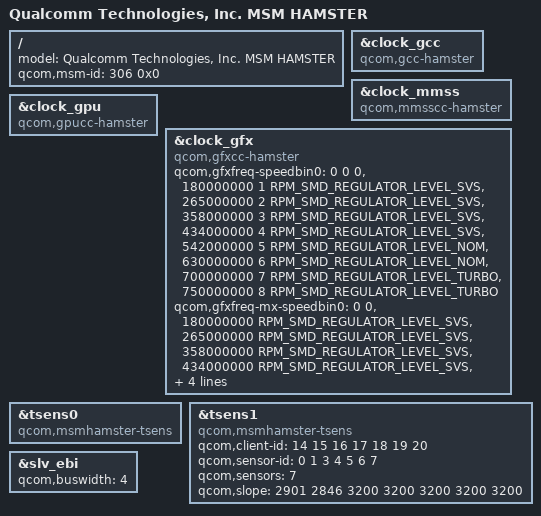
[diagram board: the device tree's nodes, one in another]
/* Copyright (c) 2016, The Linux Foundation. All rights reserved.
 *
 * This program is free software; you can redistribute it and/or modify
 * it under the terms of the GNU General Public License version 2 and
 * only version 2 as published by the Free Software Foundation.
 *
 * This program is distributed in the hope that it will be useful,
 * but WITHOUT ANY WARRANTY; without even the implied warranty of
 * MERCHANTABILITY or FITNESS FOR A PARTICULAR PURPOSE.  See the
 * GNU General Public License for more details.
 */

/*
 * As a general rule, only version-specific property overrides should be placed
 * inside this file. Common device definitions should be placed inside the
 * msm8998.dtsi file.
 */

#include "msm8998-v2.dtsi"

/ {
	model = "Qualcomm Technologies, Inc. MSM HAMSTER";
	qcom,msm-id = <306 0x0>;
};

&clock_gcc {
	compatible = "qcom,gcc-hamster";
};

&clock_mmss {
	compatible = "qcom,mmsscc-hamster";
};

&clock_gpu {
	compatible = "qcom,gpucc-hamster";
};

&clock_gfx {
	compatible = "qcom,gfxcc-hamster";
	qcom,gfxfreq-speedbin0 =
		<	  0 0				0 >,
		< 180000000 1 RPM_SMD_REGULATOR_LEVEL_SVS >,
		< 265000000 2 RPM_SMD_REGULATOR_LEVEL_SVS >,
		< 358000000 3 RPM_SMD_REGULATOR_LEVEL_SVS >,
		< 434000000 4 RPM_SMD_REGULATOR_LEVEL_SVS >,
		< 542000000 5 RPM_SMD_REGULATOR_LEVEL_NOM >,
		< 630000000 6 RPM_SMD_REGULATOR_LEVEL_NOM >,
		< 700000000 7 RPM_SMD_REGULATOR_LEVEL_TURBO >,
		< 750000000 8 RPM_SMD_REGULATOR_LEVEL_TURBO >;
	qcom,gfxfreq-mx-speedbin0 =
		<         0                           0 >,
		< 180000000 RPM_SMD_REGULATOR_LEVEL_SVS >,
		< 265000000 RPM_SMD_REGULATOR_LEVEL_SVS >,
		< 358000000 RPM_SMD_REGULATOR_LEVEL_SVS >,
		< 434000000 RPM_SMD_REGULATOR_LEVEL_SVS >,
		< 542000000 RPM_SMD_REGULATOR_LEVEL_NOM >,
		< 630000000 RPM_SMD_REGULATOR_LEVEL_NOM >,
		< 700000000 RPM_SMD_REGULATOR_LEVEL_TURBO >,
		< 750000000 RPM_SMD_REGULATOR_LEVEL_TURBO >;
};

&tsens0 {
	compatible = "qcom,msmhamster-tsens";
};

&tsens1 {
	compatible = "qcom,msmhamster-tsens";
	qcom,client-id = <14 15 16 17 18 19 20>;
	qcom,sensor-id = <0 1 3 4 5 6 7>;
	qcom,sensors = <7>;
	qcom,slope = <2901 2846 3200 3200 3200 3200 3200>;
};

&slv_ebi {
	qcom,buswidth = <4>;
};
